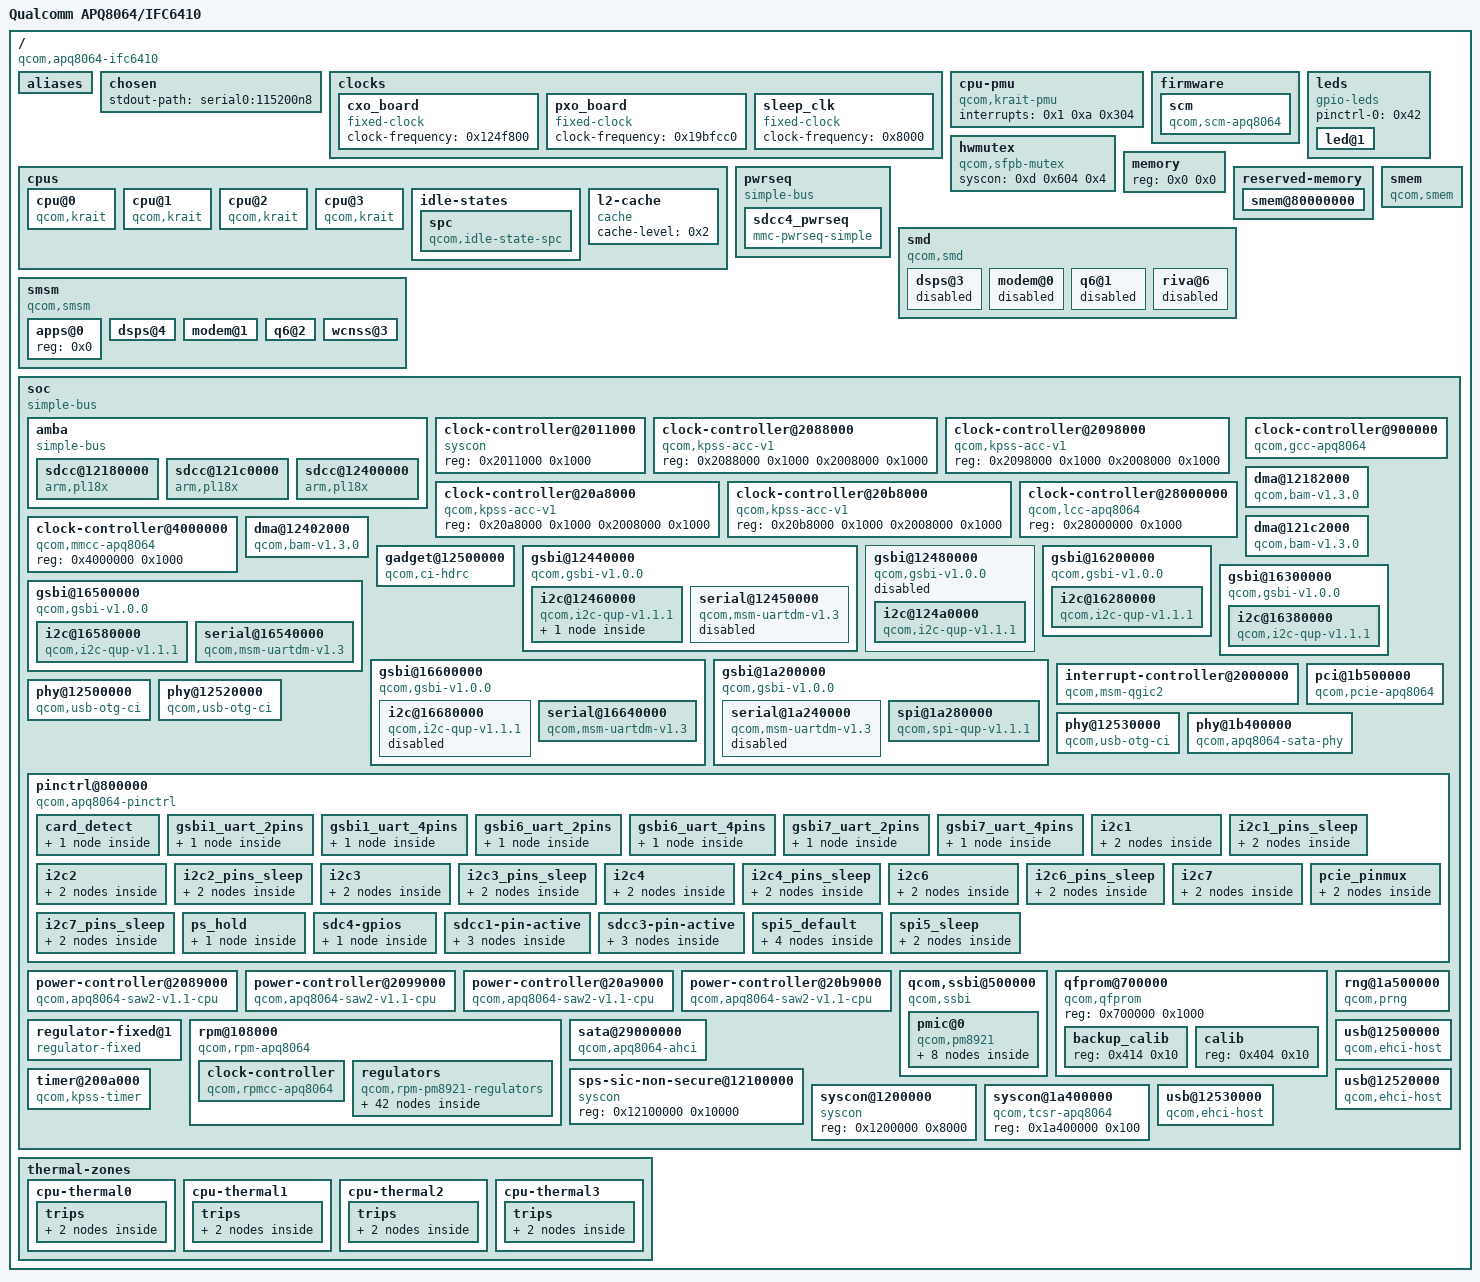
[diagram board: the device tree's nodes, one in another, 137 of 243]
/dts-v1/;

/ {
	#address-cells = <0x1>;
	#size-cells = <0x1>;
	compatible = "qcom,apq8064-ifc6410", "qcom,apq8064";
	interrupt-parent = <0x1>;
	model = "Qualcomm APQ8064/IFC6410";

	__symbols__ {
		CPU_SPC = "/cpus/idle-states/spc";
		L2 = "/cpus/l2-cache";
		acc0 = "/soc/clock-controller@2088000";
		acc1 = "/soc/clock-controller@2098000";
		acc2 = "/soc/clock-controller@20a8000";
		acc3 = "/soc/clock-controller@20b8000";
		apps_smsm = "/smsm/apps@0";
		card_detect = "/soc/pinctrl@800000/card_detect";
		cpu_alert0 = "/thermal-zones/cpu-thermal0/trips/trip0";
		cpu_alert1 = "/thermal-zones/cpu-thermal1/trips/trip0";
		cpu_alert2 = "/thermal-zones/cpu-thermal2/trips/trip0";
		cpu_alert3 = "/thermal-zones/cpu-thermal3/trips/trip0";
		cpu_crit0 = "/thermal-zones/cpu-thermal0/trips/trip1";
		cpu_crit1 = "/thermal-zones/cpu-thermal1/trips/trip1";
		cpu_crit2 = "/thermal-zones/cpu-thermal2/trips/trip1";
		cpu_crit3 = "/thermal-zones/cpu-thermal3/trips/trip1";
		dsps_smsm = "/smsm/dsps@4";
		ext_3p3v = "/soc/regulator-fixed@1";
		gadget1 = "/soc/gadget@12500000";
		gcc = "/soc/clock-controller@900000";
		gsbi1 = "/soc/gsbi@12440000";
		gsbi1_i2c = "/soc/gsbi@12440000/i2c@12460000";
		gsbi1_serial = "/soc/gsbi@12440000/serial@12450000";
		gsbi1_uart_2pins = "/soc/pinctrl@800000/gsbi1_uart_2pins";
		gsbi1_uart_4pins = "/soc/pinctrl@800000/gsbi1_uart_4pins";
		gsbi2 = "/soc/gsbi@12480000";
		gsbi2_i2c = "/soc/gsbi@12480000/i2c@124a0000";
		gsbi3 = "/soc/gsbi@16200000";
		gsbi3_i2c = "/soc/gsbi@16200000/i2c@16280000";
		gsbi4 = "/soc/gsbi@16300000";
		gsbi4_i2c = "/soc/gsbi@16300000/i2c@16380000";
		gsbi5 = "/soc/gsbi@1a200000";
		gsbi5_serial = "/soc/gsbi@1a200000/serial@1a240000";
		gsbi5_spi = "/soc/gsbi@1a200000/spi@1a280000";
		gsbi6 = "/soc/gsbi@16500000";
		gsbi6_i2c = "/soc/gsbi@16500000/i2c@16580000";
		gsbi6_serial = "/soc/gsbi@16500000/serial@16540000";
		gsbi6_uart_2pins = "/soc/pinctrl@800000/gsbi6_uart_2pins";
		gsbi6_uart_4pins = "/soc/pinctrl@800000/gsbi6_uart_4pins";
		gsbi7 = "/soc/gsbi@16600000";
		gsbi7_i2c = "/soc/gsbi@16600000/i2c@16680000";
		gsbi7_serial = "/soc/gsbi@16600000/serial@16640000";
		gsbi7_uart_2pins = "/soc/pinctrl@800000/gsbi7_uart_2pins";
		gsbi7_uart_4pins = "/soc/pinctrl@800000/gsbi7_uart_4pins";
		i2c1_pins = "/soc/pinctrl@800000/i2c1";
		i2c1_pins_sleep = "/soc/pinctrl@800000/i2c1_pins_sleep";
		i2c2_pins = "/soc/pinctrl@800000/i2c2";
		i2c2_pins_sleep = "/soc/pinctrl@800000/i2c2_pins_sleep";
		i2c3_pins = "/soc/pinctrl@800000/i2c3";
		i2c3_pins_sleep = "/soc/pinctrl@800000/i2c3_pins_sleep";
		i2c4_pins = "/soc/pinctrl@800000/i2c4";
		i2c4_pins_sleep = "/soc/pinctrl@800000/i2c4_pins_sleep";
		i2c6_pins = "/soc/pinctrl@800000/i2c6";
		i2c6_pins_sleep = "/soc/pinctrl@800000/i2c6_pins_sleep";
		i2c7_pins = "/soc/pinctrl@800000/i2c7";
		i2c7_pins_sleep = "/soc/pinctrl@800000/i2c7_pins_sleep";
		intc = "/soc/interrupt-controller@2000000";
		l2cc = "/soc/clock-controller@2011000";
		lcc = "/soc/clock-controller@28000000";
		mmcc = "/soc/clock-controller@4000000";
		modem_smsm = "/smsm/modem@1";
		notify_led = "/soc/qcom,ssbi@500000/pmic@0/gpio@150/nled";
		pcie = "/soc/pci@1b500000";
		pcie_pins = "/soc/pinctrl@800000/pcie_pinmux";
		pm8921_gpio = "/soc/qcom,ssbi@500000/pmic@0/gpio@150";
		pm8921_hdmi_switch = "/soc/rpm@108000/regulators/hdmi-switch";
		pm8921_l1 = "/soc/rpm@108000/regulators/l1";
		pm8921_l10 = "/soc/rpm@108000/regulators/l10";
		pm8921_l11 = "/soc/rpm@108000/regulators/l11";
		pm8921_l12 = "/soc/rpm@108000/regulators/l12";
		pm8921_l14 = "/soc/rpm@108000/regulators/l14";
		pm8921_l15 = "/soc/rpm@108000/regulators/l15";
		pm8921_l16 = "/soc/rpm@108000/regulators/l16";
		pm8921_l17 = "/soc/rpm@108000/regulators/l17";
		pm8921_l18 = "/soc/rpm@108000/regulators/l18";
		pm8921_l2 = "/soc/rpm@108000/regulators/l2";
		pm8921_l21 = "/soc/rpm@108000/regulators/l21";
		pm8921_l22 = "/soc/rpm@108000/regulators/l22";
		pm8921_l23 = "/soc/rpm@108000/regulators/l23";
		pm8921_l24 = "/soc/rpm@108000/regulators/l24";
		pm8921_l25 = "/soc/rpm@108000/regulators/l25";
		pm8921_l26 = "/soc/rpm@108000/regulators/l26";
		pm8921_l27 = "/soc/rpm@108000/regulators/l27";
		pm8921_l28 = "/soc/rpm@108000/regulators/l28";
		pm8921_l29 = "/soc/rpm@108000/regulators/l29";
		pm8921_l3 = "/soc/rpm@108000/regulators/l3";
		pm8921_l4 = "/soc/rpm@108000/regulators/l4";
		pm8921_l5 = "/soc/rpm@108000/regulators/l5";
		pm8921_l6 = "/soc/rpm@108000/regulators/l6";
		pm8921_l7 = "/soc/rpm@108000/regulators/l7";
		pm8921_l8 = "/soc/rpm@108000/regulators/l8";
		pm8921_l9 = "/soc/rpm@108000/regulators/l9";
		pm8921_lvs1 = "/soc/rpm@108000/regulators/lvs1";
		pm8921_lvs2 = "/soc/rpm@108000/regulators/lvs2";
		pm8921_lvs3 = "/soc/rpm@108000/regulators/lvs3";
		pm8921_lvs4 = "/soc/rpm@108000/regulators/lvs4";
		pm8921_lvs5 = "/soc/rpm@108000/regulators/lvs5";
		pm8921_lvs6 = "/soc/rpm@108000/regulators/lvs6";
		pm8921_lvs7 = "/soc/rpm@108000/regulators/lvs7";
		pm8921_mpps = "/soc/qcom,ssbi@500000/pmic@0/mpps@50";
		pm8921_ncp = "/soc/rpm@108000/regulators/ncp";
		pm8921_s1 = "/soc/rpm@108000/regulators/s1";
		pm8921_s2 = "/soc/rpm@108000/regulators/s2";
		pm8921_s3 = "/soc/rpm@108000/regulators/s3";
		pm8921_s4 = "/soc/rpm@108000/regulators/s4";
		pm8921_s7 = "/soc/rpm@108000/regulators/s7";
		pm8921_s8 = "/soc/rpm@108000/regulators/s8";
		pm8921_usb_switch = "/soc/rpm@108000/regulators/usb-switch";
		pmicintc = "/soc/qcom,ssbi@500000/pmic@0";
		ps_hold = "/soc/pinctrl@800000/ps_hold";
		q6_smsm = "/smsm/q6@2";
		qfprom = "/soc/qfprom@700000";
		rpmcc = "/soc/rpm@108000/clock-controller";
		sata0 = "/soc/sata@29000000";
		sata_phy0 = "/soc/phy@1b400000";
		saw0 = "/soc/power-controller@2089000";
		saw1 = "/soc/power-controller@2099000";
		saw2 = "/soc/power-controller@20a9000";
		saw3 = "/soc/power-controller@20b9000";
		sdc4_gpios = "/soc/pinctrl@800000/sdc4-gpios";
		sdcc1 = "/soc/amba/sdcc@12400000";
		sdcc1_pins = "/soc/pinctrl@800000/sdcc1-pin-active";
		sdcc1bam = "/soc/dma@12402000";
		sdcc3 = "/soc/amba/sdcc@12180000";
		sdcc3_pins = "/soc/pinctrl@800000/sdcc3-pin-active";
		sdcc3bam = "/soc/dma@12182000";
		sdcc4 = "/soc/amba/sdcc@121c0000";
		sdcc4_pwrseq = "/pwrseq/sdcc4_pwrseq";
		sdcc4bam = "/soc/dma@121c2000";
		sfpb_mutex = "/hwmutex";
		sfpb_wrapper_mutex = "/soc/syscon@1200000";
		smem_region = "/reserved-memory/smem@80000000";
		soc = "/soc";
		spi4 = "/soc/gsbi@1a200000/spi@1a280000";
		spi5_default = "/soc/pinctrl@800000/spi5_default";
		spi5_sleep = "/soc/pinctrl@800000/spi5_sleep";
		sps_sic_non_secure = "/soc/sps-sic-non-secure@12100000";
		tcsr = "/soc/syscon@1a400000";
		tlmm_pinmux = "/soc/pinctrl@800000";
		tsens_backup = "/soc/qfprom@700000/backup_calib";
		tsens_calib = "/soc/qfprom@700000/calib";
		usb1 = "/soc/usb@12500000";
		usb1_phy = "/soc/phy@12500000";
		usb3 = "/soc/usb@12520000";
		usb3_phy = "/soc/phy@12520000";
		usb4 = "/soc/usb@12530000";
		usb4_phy = "/soc/phy@12530000";
		wcnss_smsm = "/smsm/wcnss@3";
		wlan_default_gpios = "/soc/qcom,ssbi@500000/pmic@0/gpio@150/wlan-gpios";
	};

	aliases {
		i2c0 = "/soc/gsbi@12440000/i2c@12460000";
		i2c1 = "/soc/gsbi@12480000/i2c@124a0000";
		i2c2 = "/soc/gsbi@16200000/i2c@16280000";
		i2c3 = "/soc/gsbi@16300000/i2c@16380000";
		serial0 = "/soc/gsbi@16600000/serial@16640000";
		serial1 = "/soc/gsbi@16500000/serial@16540000";
		spi0 = "/soc/gsbi@1a200000/spi@1a280000";
	};

	chosen {
		stdout-path = "serial0:115200n8";
	};

	clocks {

		cxo_board {
			#clock-cells = <0x0>;
			clock-frequency = <0x124f800>;
			compatible = "fixed-clock";
		};

		pxo_board {
			#clock-cells = <0x0>;
			clock-frequency = <0x19bfcc0>;
			compatible = "fixed-clock";
		};

		sleep_clk {
			#clock-cells = <0x0>;
			clock-frequency = <0x8000>;
			compatible = "fixed-clock";
		};
	};

	cpu-pmu {
		compatible = "qcom,krait-pmu";
		interrupts = <0x1 0xa 0x304>;
	};

	cpus {
		#address-cells = <0x1>;
		#size-cells = <0x0>;

		cpu@0 {
			compatible = "qcom,krait";
			cpu-idle-states = <0x5>;
			device_type = "cpu";
			enable-method = "qcom,kpss-acc-v1";
			next-level-cache = <0x2>;
			qcom,acc = <0x3>;
			qcom,saw = <0x4>;
			reg = <0x0>;
		};

		cpu@1 {
			compatible = "qcom,krait";
			cpu-idle-states = <0x5>;
			device_type = "cpu";
			enable-method = "qcom,kpss-acc-v1";
			next-level-cache = <0x2>;
			qcom,acc = <0x6>;
			qcom,saw = <0x7>;
			reg = <0x1>;
		};

		cpu@2 {
			compatible = "qcom,krait";
			cpu-idle-states = <0x5>;
			device_type = "cpu";
			enable-method = "qcom,kpss-acc-v1";
			next-level-cache = <0x2>;
			qcom,acc = <0x8>;
			qcom,saw = <0x9>;
			reg = <0x2>;
		};

		cpu@3 {
			compatible = "qcom,krait";
			cpu-idle-states = <0x5>;
			device_type = "cpu";
			enable-method = "qcom,kpss-acc-v1";
			next-level-cache = <0x2>;
			qcom,acc = <0xa>;
			qcom,saw = <0xb>;
			reg = <0x3>;
		};

		idle-states {

			spc {
				compatible = "qcom,idle-state-spc", "arm,idle-state";
				entry-latency-us = <0x190>;
				exit-latency-us = <0x384>;
				min-residency-us = <0xbb8>;
				phandle = <0x5>;
			};
		};

		l2-cache {
			cache-level = <0x2>;
			compatible = "cache";
			phandle = <0x2>;
		};
	};

	firmware {

		scm {
			compatible = "qcom,scm-apq8064";
		};
	};

	hwmutex {
		#hwlock-cells = <0x1>;
		compatible = "qcom,sfpb-mutex";
		phandle = <0xf>;
		syscon = <0xd 0x604 0x4>;
	};

	leds {
		compatible = "gpio-leds";
		pinctrl-0 = <0x42>;
		pinctrl-names = "default";

		led@1 {
			default-state = "on";
			gpios = <0x41 0x12 0x0>;
			label = "apq8064:green:user1";
		};
	};

	memory {
		device_type = "memory";
		reg = <0x0 0x0>;
	};

	pwrseq {
		compatible = "simple-bus";

		sdcc4_pwrseq {
			compatible = "mmc-pwrseq-simple";
			phandle = <0x3d>;
			pinctrl-0 = <0x40>;
			pinctrl-names = "default";
			reset-gpios = <0x41 0x2b 0x1>;
		};
	};

	reserved-memory {
		#address-cells = <0x1>;
		#size-cells = <0x1>;
		ranges;

		smem@80000000 {
			no-map;
			phandle = <0xe>;
			reg = <0x80000000 0x200000>;
		};
	};

	smd {
		compatible = "qcom,smd";

		dsps@3 {
			interrupts = <0x0 0x8a 0x1>;
			qcom,ipc = <0x11 0x4080 0x0>;
			qcom,smd-edge = <0x3>;
			status = "disabled";
		};

		modem@0 {
			interrupts = <0x0 0x25 0x1>;
			qcom,ipc = <0x10 0x8 0x3>;
			qcom,smd-edge = <0x0>;
			status = "disabled";
		};

		q6@1 {
			interrupts = <0x0 0x5a 0x1>;
			qcom,ipc = <0x10 0x8 0xf>;
			qcom,smd-edge = <0x1>;
			status = "disabled";
		};

		riva@6 {
			interrupts = <0x0 0xc6 0x1>;
			qcom,ipc = <0x10 0x8 0x19>;
			qcom,smd-edge = <0x6>;
			status = "disabled";
		};
	};

	smem {
		compatible = "qcom,smem";
		hwlocks = <0xf 0x3>;
		memory-region = <0xe>;
	};

	smsm {
		#address-cells = <0x1>;
		#size-cells = <0x0>;
		compatible = "qcom,smsm";
		qcom,ipc-1 = <0x10 0x8 0x4>;
		qcom,ipc-2 = <0x10 0x8 0xe>;
		qcom,ipc-3 = <0x10 0x8 0x17>;
		qcom,ipc-4 = <0x11 0x4094 0x0>;

		apps@0 {
			#qcom,smem-state-cells = <0x1>;
			phandle = <0x4b>;
			reg = <0x0>;
		};

		dsps@4 {
			#interrupt-cells = <0x2>;
			interrupt-controller;
			interrupts = <0x0 0x89 0x1>;
			phandle = <0x4f>;
			reg = <0x4>;
		};

		modem@1 {
			#interrupt-cells = <0x2>;
			interrupt-controller;
			interrupts = <0x0 0x26 0x1>;
			phandle = <0x4c>;
			reg = <0x1>;
		};

		q6@2 {
			#interrupt-cells = <0x2>;
			interrupt-controller;
			interrupts = <0x0 0x59 0x1>;
			phandle = <0x4d>;
			reg = <0x2>;
		};

		wcnss@3 {
			#interrupt-cells = <0x2>;
			interrupt-controller;
			interrupts = <0x0 0xcc 0x1>;
			phandle = <0x4e>;
			reg = <0x3>;
		};
	};

	soc {
		#address-cells = <0x1>;
		#size-cells = <0x1>;
		compatible = "simple-bus";
		phandle = <0x50>;
		ranges;

		amba {
			#address-cells = <0x1>;
			#size-cells = <0x1>;
			compatible = "simple-bus";
			ranges;

			sdcc@12180000 {
				arm,primecell-periphid = <0x51180>;
				bus-width = <0x4>;
				cap-mmc-highspeed;
				cap-sd-highspeed;
				cd-gpios = <0x1e 0x1a 0x1>;
				clock-names = "mclk", "apb_pclk";
				clocks = <0xc 0x7a 0xc 0x70>;
				compatible = "arm,pl18x", "arm,primecell";
				dma-names = "tx", "rx";
				dmas = <0x36 0x2 0x36 0x1>;
				interrupt-names = "cmd_irq";
				interrupts = <0x0 0x66 0x4>;
				max-frequency = <0xb71b000>;
				no-1-8-v;
				phandle = <0x92>;
				pinctrl-0 = <0x38>;
				pinctrl-names = "default";
				reg = <0x12180000 0x2000>;
				status = "okay";
				vmmc-supply = <0x37>;
			};

			sdcc@121c0000 {
				arm,primecell-periphid = <0x51180>;
				bus-width = <0x4>;
				cap-mmc-highspeed;
				cap-sd-highspeed;
				clock-names = "mclk", "apb_pclk";
				clocks = <0xc 0x7b 0xc 0x71>;
				compatible = "arm,pl18x", "arm,primecell";
				dma-names = "tx", "rx";
				dmas = <0x39 0x2 0x39 0x1>;
				interrupt-names = "cmd_irq";
				interrupts = <0x0 0x65 0x4>;
				max-frequency = <0x2dc6c00>;
				mmc-pwrseq = <0x3d>;
				phandle = <0x93>;
				pinctrl-0 = <0x3a>;
				pinctrl-names = "default";
				reg = <0x121c0000 0x2000>;
				status = "okay";
				vmmc-supply = <0x3b>;
				vqmmc-supply = <0x3c>;
			};

			sdcc@12400000 {
				arm,primecell-periphid = <0x51180>;
				bus-width = <0x8>;
				cap-mmc-highspeed;
				cap-sd-highspeed;
				clock-names = "mclk", "apb_pclk";
				clocks = <0xc 0x78 0xc 0x6e>;
				compatible = "arm,pl18x", "arm,primecell";
				dma-names = "tx", "rx";
				dmas = <0x34 0x2 0x34 0x1>;
				interrupt-names = "cmd_irq";
				interrupts = <0x0 0x68 0x4>;
				max-frequency = <0x5b8d800>;
				non-removable;
				phandle = <0x91>;
				pinctrl-0 = <0x33>;
				pinctrl-names = "default";
				reg = <0x12400000 0x2000>;
				status = "okay";
				vmmc-supply = <0x35>;
				vqmmc-supply = <0x28>;
			};
		};

		clock-controller@2011000 {
			compatible = "syscon";
			phandle = <0x10>;
			reg = <0x2011000 0x1000>;
		};

		clock-controller@2088000 {
			compatible = "qcom,kpss-acc-v1";
			phandle = <0x3>;
			reg = <0x2088000 0x1000 0x2008000 0x1000>;
		};

		clock-controller@2098000 {
			compatible = "qcom,kpss-acc-v1";
			phandle = <0x6>;
			reg = <0x2098000 0x1000 0x2008000 0x1000>;
		};

		clock-controller@20a8000 {
			compatible = "qcom,kpss-acc-v1";
			phandle = <0x8>;
			reg = <0x20a8000 0x1000 0x2008000 0x1000>;
		};

		clock-controller@20b8000 {
			compatible = "qcom,kpss-acc-v1";
			phandle = <0xa>;
			reg = <0x20b8000 0x1000 0x2008000 0x1000>;
		};

		clock-controller@28000000 {
			#clock-cells = <0x1>;
			#reset-cells = <0x1>;
			compatible = "qcom,lcc-apq8064";
			phandle = <0x6a>;
			reg = <0x28000000 0x1000>;
		};

		clock-controller@4000000 {
			#clock-cells = <0x1>;
			#reset-cells = <0x1>;
			compatible = "qcom,mmcc-apq8064";
			phandle = <0x6b>;
			reg = <0x4000000 0x1000>;
		};

		clock-controller@900000 {
			#clock-cells = <0x1>;
			#reset-cells = <0x1>;
			#thermal-sensor-cells = <0x1>;
			compatible = "qcom,gcc-apq8064";
			nvmem-cell-names = "calib", "calib_backup";
			nvmem-cells = <0x26 0x27>;
			phandle = <0xc>;
			reg = <0x900000 0x4000>;
		};

		dma@12182000 {
			#dma-cells = <0x1>;
			clock-names = "bam_clk";
			clocks = <0xc 0x70>;
			compatible = "qcom,bam-v1.3.0";
			interrupts = <0x0 0x60 0x0>;
			phandle = <0x36>;
			qcom,ee = <0x0>;
			reg = <0x12182000 0x8000>;
		};

		dma@121c2000 {
			#dma-cells = <0x1>;
			clock-names = "bam_clk";
			clocks = <0xc 0x71>;
			compatible = "qcom,bam-v1.3.0";
			interrupts = <0x0 0x5f 0x0>;
			phandle = <0x39>;
			qcom,ee = <0x0>;
			reg = <0x121c2000 0x8000>;
		};

		dma@12402000 {
			#dma-cells = <0x1>;
			clock-names = "bam_clk";
			clocks = <0xc 0x6e>;
			compatible = "qcom,bam-v1.3.0";
			interrupts = <0x0 0x62 0x0>;
			phandle = <0x34>;
			qcom,ee = <0x0>;
			reg = <0x12402000 0x8000>;
		};

		gadget@12500000 {
			compatible = "qcom,ci-hdrc";
			dr_mode = "peripheral";
			interrupts = <0x0 0x64 0x0>;
			phandle = <0x8c>;
			reg = <0x12500000 0x400>;
			status = "okay";
			usb-phy = <0x2f>;
		};

		gsbi@12440000 {
			#address-cells = <0x1>;
			#size-cells = <0x1>;
			cell-index = <0x1>;
			clock-names = "iface";
			clocks = <0xc 0x93>;
			compatible = "qcom,gsbi-v1.0.0";
			phandle = <0x56>;
			qcom,mode = <0x2>;
			ranges;
			reg = <0x12440000 0x100>;
			status = "okay";
			syscon-tcsr = <0x13>;

			i2c@12460000 {
				#address-cells = <0x1>;
				#size-cells = <0x0>;
				clock-frequency = <0x30d40>;
				clock-names = "core", "iface";
				clocks = <0xc 0xb8 0xc 0x93>;
				compatible = "qcom,i2c-qup-v1.1.1";
				interrupts = <0x0 0xc2 0x0>;
				phandle = <0x58>;
				pinctrl-0 = <0x14>;
				pinctrl-1 = <0x15>;
				pinctrl-names = "default", "sleep";
				reg = <0x12460000 0x1000>;
				status = "okay";

				eeprom@52 {
					compatible = "atmel,24c128";
					pagesize = <0x20>;
					reg = <0x52>;
				};
			};

			serial@12450000 {
				clock-names = "core", "iface";
				clocks = <0xc 0xa0 0xc 0x93>;
				compatible = "qcom,msm-uartdm-v1.3", "qcom,msm-uartdm";
				interrupts = <0x0 0xc1 0x0>;
				phandle = <0x57>;
				reg = <0x12450000 0x100 0x12400000 0x3>;
				status = "disabled";
			};
		};

		gsbi@12480000 {
			#address-cells = <0x1>;
			#size-cells = <0x1>;
			cell-index = <0x2>;
			clock-names = "iface";
			clocks = <0xc 0x94>;
			compatible = "qcom,gsbi-v1.0.0";
			phandle = <0x59>;
			ranges;
			reg = <0x12480000 0x100>;
			status = "disabled";
			syscon-tcsr = <0x13>;

			i2c@124a0000 {
				#address-cells = <0x1>;
				#size-cells = <0x0>;
				clock-names = "core", "iface";
				clocks = <0xc 0xba 0xc 0x94>;
				compatible = "qcom,i2c-qup-v1.1.1";
				interrupts = <0x0 0xc4 0x0>;
				phandle = <0x5a>;
				pinctrl-0 = <0x16>;
				pinctrl-1 = <0x17>;
				pinctrl-names = "default", "sleep";
				reg = <0x124a0000 0x1000>;
			};
		};

		gsbi@16200000 {
			#address-cells = <0x1>;
			#size-cells = <0x1>;
			cell-index = <0x3>;
			clock-names = "iface";
			clocks = <0xc 0x95>;
			compatible = "qcom,gsbi-v1.0.0";
			phandle = <0x5b>;
			qcom,mode = <0x2>;
			ranges;
			reg = <0x16200000 0x100>;
			status = "okay";

			i2c@16280000 {
				#address-cells = <0x1>;
				#size-cells = <0x0>;
				clock-names = "core", "iface";
				clocks = <0xc 0xbc 0xc 0x95>;
				compatible = "qcom,i2c-qup-v1.1.1";
				interrupts = <0x0 0x97 0x0>;
				phandle = <0x5c>;
				pinctrl-0 = <0x18>;
				pinctrl-1 = <0x19>;
				pinctrl-names = "default", "sleep";
				reg = <0x16280000 0x1000>;
				status = "okay";
			};
		};

		gsbi@16300000 {
			#address-cells = <0x1>;
			#size-cells = <0x1>;
			cell-index = <0x4>;
			clock-names = "iface";
			clocks = <0xc 0x96>;
			compatible = "qcom,gsbi-v1.0.0";
			phandle = <0x5d>;
			qcom,mode = <0x2>;
			ranges;
			reg = <0x16300000 0x3>;
			status = "okay";

			i2c@16380000 {
				clock-names = "core", "iface";
				clocks = <0xc 0xbe 0xc 0x96>;
				compatible = "qcom,i2c-qup-v1.1.1";
				interrupts = <0x0 0x99 0x0>;
				phandle = <0x5e>;
				pinctrl-0 = <0x1a>;
				pinctrl-1 = <0x1b>;
				pinctrl-names = "default", "sleep";
				reg = <0x16380000 0x1000>;
				status = "okay";
			};
		};

		gsbi@16500000 {
			#address-cells = <0x1>;
			#size-cells = <0x1>;
			cell-index = <0x6>;
			clock-names = "iface";
			clocks = <0xc 0x98>;
			compatible = "qcom,gsbi-v1.0.0";
			phandle = <0x62>;
			qcom,mode = <0x4>;
			ranges;
			reg = <0x16500000 0x3>;
			status = "ok";

			i2c@16580000 {
				clock-names = "core", "iface";
				clocks = <0xc 0xc2 0xc 0x98>;
				compatible = "qcom,i2c-qup-v1.1.1";
				interrupts = <0x0 0x9d 0x0>;
				phandle = <0x64>;
				pinctrl-0 = <0x20>;
				pinctrl-1 = <0x21>;
				pinctrl-names = "default", "sleep";
				reg = <0x16580000 0x1000>;
			};

			serial@16540000 {
				clock-names = "core", "iface";
				clocks = <0xc 0xaa 0xc 0x98>;
				compatible = "qcom,msm-uartdm-v1.3", "qcom,msm-uartdm";
				interrupts = <0x0 0x9c 0x0>;
				phandle = <0x63>;
				pinctrl-0 = <0x1f>;
				pinctrl-names = "default";
				reg = <0x16540000 0x100 0x16500000 0x3>;
				status = "ok";
			};
		};

		gsbi@16600000 {
			#address-cells = <0x1>;
			#size-cells = <0x1>;
			cell-index = <0x7>;
			clock-names = "iface";
			clocks = <0xc 0x99>;
			compatible = "qcom,gsbi-v1.0.0";
			phandle = <0x65>;
			qcom,mode = <0x6>;
			ranges;
			reg = <0x16600000 0x100>;
			status = "ok";
			syscon-tcsr = <0x13>;

			i2c@16680000 {
				clock-names = "core", "iface";
				clocks = <0xc 0xc4 0xc 0x99>;
				compatible = "qcom,i2c-qup-v1.1.1";
				interrupts = <0x0 0x9f 0x0>;
				phandle = <0x67>;
				pinctrl-0 = <0x23>;
				pinctrl-1 = <0x24>;
				pinctrl-names = "default", "sleep";
				reg = <0x16680000 0x1000>;
				status = "disabled";
			};

			serial@16640000 {
				clock-names = "core", "iface";
				clocks = <0xc 0xac 0xc 0x99>;
				compatible = "qcom,msm-uartdm-v1.3", "qcom,msm-uartdm";
				interrupts = <0x0 0x9e 0x0>;
				phandle = <0x66>;
				pinctrl-0 = <0x22>;
				pinctrl-names = "default";
				reg = <0x16640000 0x1000 0x16600000 0x1000>;
				status = "ok";
			};
		};

		gsbi@1a200000 {
			#address-cells = <0x1>;
			#size-cells = <0x1>;
			cell-index = <0x5>;
			clock-names = "iface";
			clocks = <0xc 0x97>;
			compatible = "qcom,gsbi-v1.0.0";
			phandle = <0x5f>;
			qcom,mode = <0x3>;
			ranges;
			reg = <0x1a200000 0x3>;
			status = "okay";

			serial@1a240000 {
				clock-names = "core", "iface";
				clocks = <0xc 0xa8 0xc 0x97>;
				compatible = "qcom,msm-uartdm-v1.3", "qcom,msm-uartdm";
				interrupts = <0x0 0x9a 0x0>;
				phandle = <0x60>;
				reg = <0x1a240000 0x100 0x1a200000 0x3>;
				status = "disabled";
			};

			spi@1a280000 {
				#address-cells = <0x1>;
				#size-cells = <0x0>;
				clock-names = "core", "iface";
				clocks = <0xc 0xc0 0xc 0x97>;
				compatible = "qcom,spi-qup-v1.1.1";
				cs-gpios = <0x1e 0x35 0x0>;
				interrupts = <0x0 0x9b 0x0>;
				num-cs = <0x1>;
				phandle = <0x61>;
				pinctrl-0 = <0x1c>;
				pinctrl-1 = <0x1d>;
				pinctrl-names = "default", "sleep";
				reg = <0x1a280000 0x1000>;
				status = "okay";
			};
		};

		interrupt-controller@2000000 {
			#interrupt-cells = <0x3>;
			compatible = "qcom,msm-qgic2";
			interrupt-controller;
			phandle = <0x1>;
			reg = <0x2000000 0x1000 0x2002000 0x1000>;
		};

		pci@1b500000 {
			#address-cells = <0x3>;
			#interrupt-cells = <0x1>;
			#size-cells = <0x2>;
			bus-range = <0x0 0xff>;
			clock-names = "core", "iface", "phy";
			clocks = <0xc 0x2b 0xc 0x2e 0xc 0x2d>;
			compatible = "qcom,pcie-apq8064", "snps,dw-pcie";
			device_type = "pci";
			interrupt-map = <0x0 0x0 0x0 0x1 0x1 0x0 0x24 0x4 0x0 0x0 0x0 0x2 0x1 0x0 0x25 0x4 0x0 0x0 0x0 0x3 0x1 0x0 0x26 0x4 0x0 0x0 0x0 0x4 0x1 0x0 0x27 0x4>;
			interrupt-map-mask = <0x0 0x0 0x0 0x7>;
			interrupt-names = "msi";
			interrupts = <0x0 0xee 0x0>;
			linux,pci-domain = <0x0>;
			num-lanes = <0x1>;
			perst-gpio = <0x1e 0x1b 0x1>;
			phandle = <0x94>;
			pinctrl-0 = <0x3f>;
			pinctrl-names = "default";
			ranges = <0x81000000 0x0 0x0 0xfe00000 0x0 0x100000 0x82000000 0x0 0x0 0x8000000 0x0 0x7e00000>;
			reg = <0x1b500000 0x1000 0x1b502000 0x80 0x1b600000 0x100 0xff00000 0x100000>;
			reg-names = "dbi", "elbi", "parf", "config";
			reset-names = "axi", "ahb", "por", "pci", "phy";
			resets = <0xc 0x6c 0xc 0x6b 0xc 0x6a 0xc 0x69 0xc 0x68>;
			status = "ok";
			vdda-supply = <0x2b>;
			vdda_phy-supply = <0x3e>;
			vdda_refclk-supply = <0x3b>;
		};

		phy@12500000 {
			clock-names = "core", "iface";
			clocks = <0xc 0x80 0xc 0x7e>;
			compatible = "qcom,usb-otg-ci";
			interrupts = <0x0 0x64 0x0>;
			phandle = <0x2f>;
			reg = <0x12500000 0x400>;
			reset-names = "link";
			resets = <0xc 0x40>;
			status = "okay";
			v1p8-supply = <0x2d>;
			v3p3-supply = <0x2c>;
			vddcx-supply = <0x2b>;
		};

		phy@12520000 {
			clock-names = "core", "iface";
			clocks = <0xc 0x129 0xc 0x127>;
			compatible = "qcom,usb-otg-ci";
			dr_mode = "host";
			interrupts = <0x0 0xbc 0x0>;
			phandle = <0x30>;
			reg = <0x12520000 0x400>;
			reset-names = "link";
			resets = <0xc 0x64>;
			status = "okay";
			v1p8-supply = <0x2e>;
			v3p3-supply = <0x2c>;
			vddcx-supply = <0x2b>;
		};

		phy@12530000 {
			clock-names = "core", "iface";
			clocks = <0xc 0x12c 0xc 0x12a>;
			compatible = "qcom,usb-otg-ci";
			dr_mode = "host";
			interrupts = <0x0 0xd7 0x0>;
			phandle = <0x31>;
			reg = <0x12530000 0x400>;
			reset-names = "link";
			resets = <0xc 0x65>;
			status = "okay";
			v1p8-supply = <0x2e>;
			v3p3-supply = <0x2c>;
			vddcx-supply = <0x2b>;
		};

		phy@1b400000 {
			#phy-cells = <0x0>;
			clock-names = "cfg";
			clocks = <0xc 0x12d>;
			compatible = "qcom,apq8064-sata-phy";
			phandle = <0x32>;
			reg = <0x1b400000 0x200>;
			reg-names = "phy_mem";
			status = "okay";
		};

		pinctrl@800000 {
			#gpio-cells = <0x2>;
			#interrupt-cells = <0x2>;
			compatible = "qcom,apq8064-pinctrl";
			gpio-controller;
			interrupt-controller;
			interrupts = <0x0 0x10 0x4>;
			phandle = <0x1e>;
			pinctrl-0 = <0x12>;
			pinctrl-names = "default";
			reg = <0x800000 0x4000>;

			card_detect {
				phandle = <0x38>;

				mux {
					bias-disable;
					function = "gpio";
					pins = "gpio26";
				};
			};

			gsbi1_uart_2pins {
				phandle = <0x52>;

				mux {
					function = "gsbi1";
					pins = "gpio18", "gpio19";
				};
			};

			gsbi1_uart_4pins {
				phandle = <0x53>;

				mux {
					function = "gsbi1";
					pins = "gpio18", "gpio19", "gpio20", "gpio21";
				};
			};

			gsbi6_uart_2pins {
				phandle = <0x54>;

				mux {
					function = "gsbi6";
					pins = "gpio14", "gpio15";
				};
			};

			gsbi6_uart_4pins {
				phandle = <0x1f>;

				mux {
					function = "gsbi6";
					pins = "gpio14", "gpio15", "gpio16", "gpio17";
				};
			};

			gsbi7_uart_2pins {
				phandle = <0x22>;

				mux {
					function = "gsbi7";
					pins = "gpio82", "gpio83";
				};
			};

			gsbi7_uart_4pins {
				phandle = <0x55>;

				mux {
					function = "gsbi7";
					pins = "gpio82", "gpio83", "gpio84", "gpio85";
				};
			};

			i2c1 {
				phandle = <0x14>;

				mux {
					function = "gsbi1";
					pins = "gpio20", "gpio21";
				};

				pinconf {
					bias-disable;
					drive-strength = <0x10>;
					pins = "gpio20", "gpio21";
				};
			};

			i2c1_pins_sleep {
				phandle = <0x15>;

				mux {
					function = "gpio";
					pins = "gpio20", "gpio21";
				};

				pinconf {
					bias-disable = <0x0>;
					drive-strength = <0x2>;
					pins = "gpio20", "gpio21";
				};
			};

			i2c2 {
				phandle = <0x16>;

				mux {
					function = "gsbi2";
					pins = "gpio24", "gpio25";
				};

				pinconf {
					bias-disable;
					drive-strength = <0x10>;
					pins = "gpio24", "gpio25";
				};
			};

			i2c2_pins_sleep {
				phandle = <0x17>;

				mux {
					function = "gpio";
					pins = "gpio24", "gpio25";
				};

				pinconf {
					bias-disable = <0x0>;
					drive-strength = <0x2>;
					pins = "gpio24", "gpio25";
				};
			};

			i2c3 {
				phandle = <0x18>;

				mux {
					function = "gsbi3";
					pins = "gpio8", "gpio9";
				};

				pinconf {
					bias-disable;
					drive-strength = <0x10>;
					pins = "gpio8", "gpio9";
				};
			};

			i2c3_pins_sleep {
				phandle = <0x19>;

				mux {
					function = "gpio";
					pins = "gpio8", "gpio9";
				};

				pinconf {
					bias-disable = <0x0>;
					drive-strength = <0x2>;
					pins = "gpio8", "gpio9";
				};
			};

			i2c4 {
				phandle = <0x1a>;

				mux {
					function = "gsbi4";
					pins = "gpio12", "gpio13";
				};

				pinconf {
					bias-disable;
					drive-strength = <0x10>;
					pins = "gpio12", "gpio13";
				};
			};

			i2c4_pins_sleep {
				phandle = <0x1b>;

				mux {
					function = "gpio";
					pins = "gpio12", "gpio13";
				};

				pinconf {
					bias-disable = <0x0>;
					drive-strength = <0x2>;
					pins = "gpio12", "gpio13";
				};
			};

			i2c6 {
				phandle = <0x20>;

				mux {
					function = "gsbi6";
					pins = "gpio16", "gpio17";
				};

				pinconf {
					bias-disable;
					drive-strength = <0x10>;
					pins = "gpio16", "gpio17";
				};
			};

			i2c6_pins_sleep {
				phandle = <0x21>;

				mux {
					function = "gpio";
					pins = "gpio16", "gpio17";
				};

				pinconf {
					bias-disable = <0x0>;
					drive-strength = <0x2>;
					pins = "gpio16", "gpio17";
				};
			};

			i2c7 {
				phandle = <0x23>;

				mux {
					function = "gsbi7";
					pins = "gpio84", "gpio85";
				};

				pinconf {
					bias-disable;
					drive-strength = <0x10>;
					pins = "gpio84", "gpio85";
				};
			};

			i2c7_pins_sleep {
				phandle = <0x24>;

				mux {
					function = "gpio";
					pins = "gpio84", "gpio85";
				};

				pinconf {
					bias-disable = <0x0>;
					drive-strength = <0x2>;
					pins = "gpio84", "gpio85";
				};
			};

			pcie_pinmux {
				phandle = <0x3f>;

				conf {
					bias-disable;
					drive-strength = <0xc>;
					pins = "gpio27";
				};

				mux {
					function = "gpio";
					pins = "gpio27";
				};
			};

			ps_hold {
				phandle = <0x12>;

				mux {
					function = "ps_hold";
					pins = "gpio78";
				};
			};

			sdc4-gpios {
				phandle = <0x3a>;

				pios {
					function = "sdc4";
					pins = "gpio63", "gpio64", "gpio65", "gpio66", "gpio67", "gpio68";
				};
			};

			sdcc1-pin-active {
				phandle = <0x33>;

				clk {
					bias-disable;
					drive-strengh = <0x10>;
					pins = "sdc1_clk";
				};

				cmd {
					bias-pull-up;
					drive-strengh = <0xa>;
					pins = "sdc1_cmd";
				};

				data {
					bias-pull-up;
					drive-strengh = <0xa>;
					pins = "sdc1_data";
				};
			};

			sdcc3-pin-active {
				phandle = <0x51>;

				clk {
					bias-disable;
					drive-strengh = <0x8>;
					pins = "sdc3_clk";
				};

				cmd {
					bias-pull-up;
					drive-strengh = <0x8>;
					pins = "sdc3_cmd";
				};

				data {
					bias-pull-up;
					drive-strengh = <0x8>;
					pins = "sdc3_data";
				};
			};

			spi5_default {
				phandle = <0x1c>;

				pinconf {
					bias-disable;
					drive-strength = <0x10>;
					pins = "gpio51", "gpio52", "gpio54";
				};

				pinconf_cs {
					bias-disable;
					drive-strength = <0x10>;
					output-high;
					pins = "gpio53";
				};

				pinmux {
					function = "gsbi5";
					pins = "gpio51", "gpio52", "gpio54";
				};

				pinmux_cs {
					function = "gpio";
					pins = "gpio53";
				};
			};

			spi5_sleep {
				phandle = <0x1d>;

				pinconf {
					bias-pull-down;
					drive-strength = <0x2>;
					pins = "gpio51", "gpio52", "gpio53", "gpio54";
				};

				pinmux {
					function = "gpio";
					pins = "gpio51", "gpio52", "gpio53", "gpio54";
				};
			};
		};

		power-controller@2089000 {
			compatible = "qcom,apq8064-saw2-v1.1-cpu", "qcom,saw2";
			phandle = <0x4>;
			reg = <0x2089000 0x1000 0x2009000 0x1000>;
			regulator;
		};

		power-controller@2099000 {
			compatible = "qcom,apq8064-saw2-v1.1-cpu", "qcom,saw2";
			phandle = <0x7>;
			reg = <0x2099000 0x1000 0x2009000 0x1000>;
			regulator;
		};

		power-controller@20a9000 {
			compatible = "qcom,apq8064-saw2-v1.1-cpu", "qcom,saw2";
			phandle = <0x9>;
			reg = <0x20a9000 0x1000 0x2009000 0x1000>;
			regulator;
		};

		power-controller@20b9000 {
			compatible = "qcom,apq8064-saw2-v1.1-cpu", "qcom,saw2";
			phandle = <0xb>;
			reg = <0x20b9000 0x1000 0x2009000 0x1000>;
			regulator;
		};

		qcom,ssbi@500000 {
			compatible = "qcom,ssbi";
			qcom,controller-type = "pmic-arbiter";
			reg = <0x500000 0x1000>;

			pmic@0 {
				#address-cells = <0x1>;
				#interrupt-cells = <0x2>;
				#size-cells = <0x0>;
				compatible = "qcom,pm8921";
				interrupt-controller;
				interrupt-parent = <0x1e>;
				interrupts = <0x4a 0x8>;
				phandle = <0x25>;

				gpio@150 {
					#gpio-cells = <0x2>;
					compatible = "qcom,pm8921-gpio", "qcom,ssbi-gpio";
					gpio-controller;
					interrupts = <0xc0 0x0 0xc1 0x0 0xc2 0x0 0xc3 0x0 0xc4 0x0 0xc5 0x0 0xc6 0x0 0xc7 0x0 0xc8 0x0 0xc9 0x0 0xca 0x0 0xcb 0x0 0xcc 0x0 0xcd 0x0 0xce 0x0 0xcf 0x0 0xd0 0x0 0xd1 0x0 0xd2 0x0 0xd3 0x0 0xd4 0x0 0xd5 0x0 0xd6 0x0 0xd7 0x0 0xd8 0x0 0xd9 0x0 0xda 0x0 0xdb 0x0 0xdc 0x0 0xdd 0x0 0xde 0x0 0xdf 0x0 0xe0 0x0 0xe1 0x0 0xe2 0x0 0xe3 0x0 0xe4 0x0 0xe5 0x0 0xe6 0x0 0xe7 0x0 0xe8 0x0 0xe9 0x0 0xea 0x0 0xeb 0x0>;
					phandle = <0x41>;
					reg = <0x150>;

					nled {
						phandle = <0x42>;

						pios {
							bias-disable;
							function = "normal";
							pins = "gpio18";
							power-source = <0x2>;
						};
					};

					wlan-gpios {
						phandle = <0x40>;

						pios {
							bias-disable;
							function = "normal";
							pins = "gpio43";
							power-source = <0x2>;
						};
					};
				};

				mpps@50 {
					#gpio-cells = <0x2>;
					compatible = "qcom,pm8921-mpp", "qcom,ssbi-mpp";
					gpio-controller;
					interrupts = <0x80 0x0 0x81 0x0 0x82 0x0 0x83 0x0 0x84 0x0 0x85 0x0 0x86 0x0 0x87 0x0 0x88 0x0 0x89 0x0 0x8a 0x0 0x8b 0x0>;
					phandle = <0x68>;
					reg = <0x50>;
				};

				pwrkey@1c {
					compatible = "qcom,pm8921-pwrkey";
					debounce = <0x3d09>;
					interrupt-parent = <0x25>;
					interrupts = <0x32 0x1 0x33 0x1>;
					pull-up;
					reg = <0x1c>;
				};

				rtc@11d {
					allow-set-time;
					compatible = "qcom,pm8921-rtc";
					interrupt-parent = <0x25>;
					interrupts = <0x27 0x1>;
					reg = <0x11d>;
				};
			};
		};

		qfprom@700000 {
			#address-cells = <0x1>;
			#size-cells = <0x1>;
			compatible = "qcom,qfprom";
			phandle = <0x69>;
			ranges;
			reg = <0x700000 0x1000>;

			backup_calib {
				phandle = <0x27>;
				reg = <0x414 0x10>;
			};

			calib {
				phandle = <0x26>;
				reg = <0x404 0x10>;
			};
		};

		regulator-fixed@1 {
			compatible = "regulator-fixed";
			enable-active-high;
			gpio = <0x1e 0x4d 0x0>;
			phandle = <0x3b>;
			regulator-boot-on;
			regulator-max-microvolt = <0x325aa0>;
			regulator-min-microvolt = <0x325aa0>;
			regulator-name = "ext_3p3v";
			regulator-type = "voltage";
			startup-delay-us = <0x0>;
		};

		rng@1a500000 {
			clock-names = "core";
			clocks = <0xc 0x108>;
			compatible = "qcom,prng";
			reg = <0x1a500000 0x200>;
		};

		rpm@108000 {
			compatible = "qcom,rpm-apq8064";
			interrupt-names = "ack", "err", "wakeup";
			interrupts = <0x0 0x13 0x1 0x0 0x15 0x1 0x0 0x16 0x1>;
			qcom,ipc = <0x10 0x8 0x2>;
			reg = <0x108000 0x1000>;

			clock-controller {
				#clock-cells = <0x1>;
				compatible = "qcom,rpmcc-apq8064", "qcom,rpmcc";
				phandle = <0x6c>;
			};

			regulators {
				compatible = "qcom,rpm-pm8921-regulators";
				vdd_l1_l2_l12_l18-supply = <0x28>;
				vdd_l24-supply = <0x29>;
				vdd_l25-supply = <0x29>;
				vdd_l26-supply = <0x2a>;
				vdd_l27-supply = <0x2a>;
				vdd_l28-supply = <0x2a>;
				vin_lvs1_3_6-supply = <0x28>;
				vin_lvs2-supply = <0x29>;
				vin_lvs4_5_7-supply = <0x28>;

				hdmi-switch {
					bias-pull-down;
					phandle = <0x8a>;
				};

				l1 {
					phandle = <0x6f>;
				};

				l10 {
					phandle = <0x74>;
				};

				l11 {
					phandle = <0x75>;
				};

				l12 {
					phandle = <0x76>;
				};

				l14 {
					phandle = <0x77>;
				};

				l15 {
					phandle = <0x78>;
				};

				l16 {
					phandle = <0x79>;
				};

				l17 {
					phandle = <0x7a>;
				};

				l18 {
					phandle = <0x7b>;
				};

				l2 {
					phandle = <0x70>;
				};

				l21 {
					phandle = <0x7c>;
				};

				l22 {
					phandle = <0x7d>;
				};

				l23 {
					bias-pull-down;
					phandle = <0x2e>;
					regulator-max-microvolt = <0x1cfde0>;
					regulator-min-microvolt = <0x19f0a0>;
				};

				l24 {
					phandle = <0x7e>;
				};

				l25 {
					phandle = <0x7f>;
				};

				l26 {
					phandle = <0x80>;
				};

				l27 {
					phandle = <0x81>;
				};

				l28 {
					phandle = <0x82>;
				};

				l29 {
					phandle = <0x83>;
				};

				l3 {
					bias-pull-down;
					phandle = <0x2c>;
					regulator-max-microvolt = <0x325aa0>;
					regulator-min-microvolt = <0x2e8a10>;
				};

				l4 {
					bias-pull-down;
					phandle = <0x2d>;
					regulator-max-microvolt = <0x1b7740>;
					regulator-min-microvolt = <0xf4240>;
				};

				l5 {
					bias-pull-down;
					phandle = <0x35>;
					regulator-max-microvolt = <0x2dc6c0>;
					regulator-min-microvolt = <0x29f630>;
				};

				l6 {
					bias-pull-down;
					phandle = <0x37>;
					regulator-max-microvolt = <0x2d0370>;
					regulator-min-microvolt = <0x2d0370>;
				};

				l7 {
					phandle = <0x71>;
				};

				l8 {
					phandle = <0x72>;
				};

				l9 {
					phandle = <0x73>;
				};

				lvs1 {
					bias-pull-down;
					phandle = <0x3c>;
				};

				lvs2 {
					phandle = <0x84>;
				};

				lvs3 {
					phandle = <0x85>;
				};

				lvs4 {
					phandle = <0x86>;
				};

				lvs5 {
					phandle = <0x87>;
				};

				lvs6 {
					bias-pull-down;
					phandle = <0x3e>;
				};

				lvs7 {
					phandle = <0x88>;
				};

				ncp {
					phandle = <0x8b>;
				};

				s1 {
					bias-pull-down;
					phandle = <0x29>;
					qcom,switch-mode-frequency = <0x30d400>;
					regulator-always-on;
					regulator-max-microvolt = <0x12b128>;
					regulator-min-microvolt = <0x12b128>;
				};

				s2 {
					phandle = <0x6d>;
				};

				s3 {
					phandle = <0x2b>;
					qcom,switch-mode-frequency = <0x493e00>;
					regulator-max-microvolt = <0x155cc0>;
					regulator-min-microvolt = <0xf4240>;
				};

				s4 {
					phandle = <0x28>;
					qcom,switch-mode-frequency = <0x30d400>;
					regulator-max-microvolt = <0x1b7740>;
					regulator-min-microvolt = <0x1b7740>;
				};

				s7 {
					phandle = <0x2a>;
					qcom,switch-mode-frequency = <0x30d400>;
					regulator-max-microvolt = <0x13d620>;
					regulator-min-microvolt = <0x13d620>;
				};

				s8 {
					phandle = <0x6e>;
				};

				usb-switch {
					phandle = <0x89>;
				};
			};
		};

		sata@29000000 {
			assigned-clock-rates = <0x5f5e100 0x5f5e100>;
			assigned-clocks = <0xc 0xef 0xc 0xf0>;
			clock-names = "slave_iface", "iface", "bus", "rxoob", "core_pmalive";
			clocks = <0xc 0x3b 0xc 0xed 0xc 0x12e 0xc 0xef 0xc 0xf0>;
			compatible = "qcom,apq8064-ahci", "generic-ahci";
			interrupts = <0x0 0xd1 0x0>;
			phandle = <0x90>;
			phy-names = "sata-phy";
			phys = <0x32>;
			ports-implemented = <0x1>;
			reg = <0x29000000 0x180>;
			status = "okay";
			target-supply = <0x28>;
		};

		sps-sic-non-secure@12100000 {
			compatible = "syscon";
			phandle = <0x11>;
			reg = <0x12100000 0x10000>;
		};

		syscon@1200000 {
			compatible = "syscon";
			phandle = <0xd>;
			reg = <0x1200000 0x8000>;
		};

		syscon@1a400000 {
			compatible = "qcom,tcsr-apq8064", "syscon";
			phandle = <0x13>;
			reg = <0x1a400000 0x100>;
		};

		timer@200a000 {
			clock-frequency = <0x19bfcc0 0x8000>;
			compatible = "qcom,kpss-timer", "qcom,kpss-wdt-apq8064", "qcom,msm-timer";
			cpu-offset = <0x80000>;
			interrupts = <0x1 0x1 0x301 0x1 0x2 0x301 0x1 0x3 0x301>;
			reg = <0x200a000 0x100>;
		};

		usb@12500000 {
			compatible = "qcom,ehci-host";
			interrupts = <0x0 0x64 0x0>;
			phandle = <0x8d>;
			reg = <0x12500000 0x400>;
			status = "okay";
			usb-phy = <0x2f>;
		};

		usb@12520000 {
			compatible = "qcom,ehci-host";
			interrupts = <0x0 0xbc 0x0>;
			phandle = <0x8e>;
			reg = <0x12520000 0x400>;
			status = "okay";
			usb-phy = <0x30>;
		};

		usb@12530000 {
			compatible = "qcom,ehci-host";
			interrupts = <0x0 0xd7 0x0>;
			phandle = <0x8f>;
			reg = <0x12530000 0x400>;
			status = "okay";
			usb-phy = <0x31>;
		};
	};

	thermal-zones {

		cpu-thermal0 {
			coefficients = <0x4af 0x0>;
			polling-delay = <0x3e8>;
			polling-delay-passive = <0xfa>;
			thermal-sensors = <0xc 0x7>;

			trips {

				trip0 {
					hysteresis = <0x7d0>;
					phandle = <0x43>;
					temperature = <0x124f8>;
					type = "passive";
				};

				trip1 {
					hysteresis = <0x7d0>;
					phandle = <0x44>;
					temperature = <0x1adb0>;
					type = "critical";
				};
			};
		};

		cpu-thermal1 {
			coefficients = <0x46c 0x0>;
			polling-delay = <0x3e8>;
			polling-delay-passive = <0xfa>;
			thermal-sensors = <0xc 0x8>;

			trips {

				trip0 {
					hysteresis = <0x7d0>;
					phandle = <0x45>;
					temperature = <0x124f8>;
					type = "passive";
				};

				trip1 {
					hysteresis = <0x7d0>;
					phandle = <0x46>;
					temperature = <0x1adb0>;
					type = "critical";
				};
			};
		};

		cpu-thermal2 {
			coefficients = <0x4af 0x0>;
			polling-delay = <0x3e8>;
			polling-delay-passive = <0xfa>;
			thermal-sensors = <0xc 0x9>;

			trips {

				trip0 {
					hysteresis = <0x7d0>;
					phandle = <0x47>;
					temperature = <0x124f8>;
					type = "passive";
				};

				trip1 {
					hysteresis = <0x7d0>;
					phandle = <0x48>;
					temperature = <0x1adb0>;
					type = "critical";
				};
			};
		};

		cpu-thermal3 {
			coefficients = <0x46c 0x0>;
			polling-delay = <0x3e8>;
			polling-delay-passive = <0xfa>;
			thermal-sensors = <0xc 0xa>;

			trips {

				trip0 {
					hysteresis = <0x7d0>;
					phandle = <0x49>;
					temperature = <0x124f8>;
					type = "passive";
				};

				trip1 {
					hysteresis = <0x7d0>;
					phandle = <0x4a>;
					temperature = <0x1adb0>;
					type = "critical";
				};
			};
		};
	};
};
